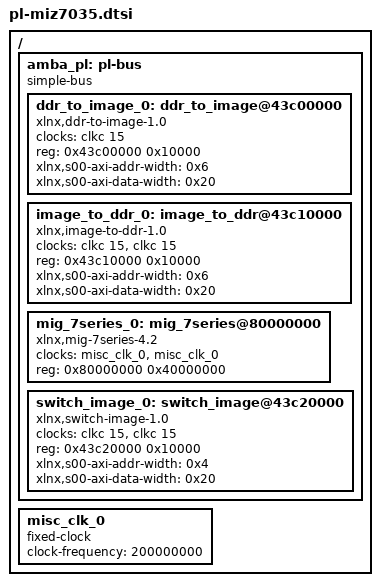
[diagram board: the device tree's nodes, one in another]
/*
 * CAUTION: This file is automatically generated by Xilinx.
 * Version: XSCT 
 * Today is: Fri Jul 17 06:31:37 2026
 */


/ {
	amba_pl: pl-bus {
		#address-cells = <1>;
		#size-cells = <1>;
		compatible = "simple-bus";
		ranges ;
		ddr_to_image_0: ddr_to_image@43c00000 {
			clock-names = "s00_axi_aclk";
			clocks = <&clkc 15>;
			compatible = "xlnx,ddr-to-image-1.0";
			reg = <0x43c00000 0x10000>;
			xlnx,s00-axi-addr-width = <0x6>;
			xlnx,s00-axi-data-width = <0x20>;
		};
		image_to_ddr_0: image_to_ddr@43c10000 {
			clock-names = "image_clk", "s00_axi_aclk";
			clocks = <&clkc 15>, <&clkc 15>;
			compatible = "xlnx,image-to-ddr-1.0";
			reg = <0x43c10000 0x10000>;
			xlnx,s00-axi-addr-width = <0x6>;
			xlnx,s00-axi-data-width = <0x20>;
		};
		mig_7series_0: mig_7series@80000000 {
			clock-names = "clk_ref_i", "sys_clk_i";
			clocks = <&misc_clk_0>, <&misc_clk_0>;
			compatible = "xlnx,mig-7series-4.2";
			reg = <0x80000000 0x40000000>;
		};
		switch_image_0: switch_image@43c20000 {
			clock-names = "clk", "s00_axi_aclk";
			clocks = <&clkc 15>, <&clkc 15>;
			compatible = "xlnx,switch-image-1.0";
			reg = <0x43c20000 0x10000>;
			xlnx,s00-axi-addr-width = <0x4>;
			xlnx,s00-axi-data-width = <0x20>;
		};
	};
	misc_clk_0: misc_clk_0 {
		#clock-cells = <0>;
		clock-frequency = <200000000>;
		compatible = "fixed-clock";
	};
};
